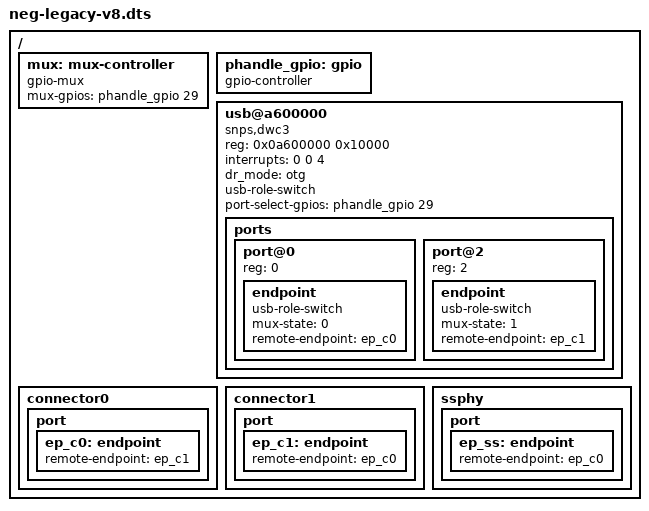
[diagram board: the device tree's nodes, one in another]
/dts-v1/;

/ {
	#address-cells = <1>;
	#size-cells = <1>;

	mux: mux-controller {
		compatible = "gpio-mux";
		#mux-control-cells = <0>;
		mux-gpios = <&phandle_gpio 29 0>;
	};

	phandle_gpio: gpio {
		#gpio-cells = <2>;
		gpio-controller;
	};

	usb@a600000 {
		compatible = "snps,dwc3";
		reg = <0x0a600000 0x10000>;
		interrupts = <0 0 4>;
		dr_mode = "otg";
		usb-role-switch;
		port-select-gpios = <&phandle_gpio 29 0>;

		ports {
			#address-cells = <1>;
			#size-cells = <0>;

			port@0 {
				reg = <0>;

				endpoint {
					usb-role-switch;
					mux-state = <0>;
					remote-endpoint = <&ep_c0>;
				};
			};

			port@2 {
				reg = <2>;

				endpoint {
					usb-role-switch;
					mux-state = <1>;
					remote-endpoint = <&ep_c1>;
				};
			};
		};
	};

	connector0 {
		port {
			ep_c0: endpoint {
				remote-endpoint = <&ep_c1>;
			};
		};
	};

	connector1 {
		port {
			ep_c1: endpoint {
				remote-endpoint = <&ep_c0>;
			};
		};
	};

	ssphy {
		port {
			ep_ss: endpoint {
				remote-endpoint = <&ep_c0>;
			};
		};
	};
};
